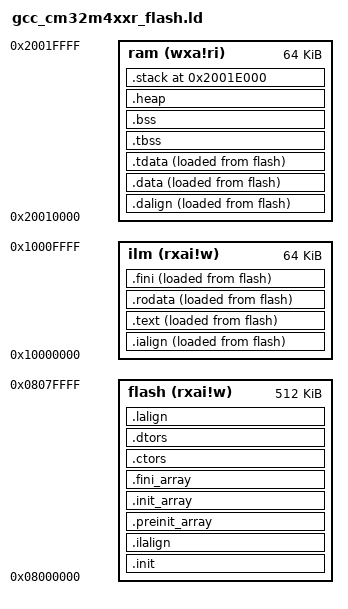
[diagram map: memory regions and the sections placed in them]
/*
 * Copyright (c) 2019 Nuclei Limited. All rights reserved.
 *
 * SPDX-License-Identifier: Apache-2.0
 *
 * Licensed under the Apache License, Version 2.0 (the License); you may
 * not use this file except in compliance with the License.
 * You may obtain a copy of the License at
 *
 * www.apache.org/licenses/LICENSE-2.0
 *
 * Unless required by applicable law or agreed to in writing, software
 * distributed under the License is distributed on an AS IS BASIS, WITHOUT
 * WARRANTIES OR CONDITIONS OF ANY KIND, either express or implied.
 * See the License for the specific language governing permissions and
 * limitations under the License.
 */
/******************************************************************************
 * @file     gcc_cm32m4xxr.ld
 * @brief    GNU Linker Script for Nuclei N/NX based device
 * @version  V1.0.0
 * @date     29. Jun 2020
 ******************************************************************************/

/*********** Use Configuration Wizard in Context Menu *************************/

OUTPUT_ARCH( "riscv" )
/********************* Flash Configuration ************************************
 * <h> Flash Configuration
 * <o0> Flash Base Address <0x0-0xFFFFFFFF:8>
 * <o1> Flash Size (in Bytes) <0x0-0xFFFFFFFF:8>
 * </h>
 */
__FLASH_BASE = 0x08000000;
__FLASH_SIZE = 0x00080000;	/* 512K user flash */

/*--------------------- ILM RAM Configuration ---------------------------
 * <h> ILM RAM Configuration
 * <o0> ILM RAM Base Address    <0x0-0xFFFFFFFF:8>
 * <o1> ILM RAM Size (in Bytes) <0x0-0xFFFFFFFF:8>
 * </h>
 */
__ILM_RAM_BASE = 0x10000000;
__ILM_RAM_SIZE = 0x00010000;	/* When used for code, set its size a proper value.
								   Note that ILM and RAM share 128K space. */

/*--------------------- Embedded RAM Configuration ---------------------------
 * <h> RAM Configuration
 * <o0> RAM Base Address    <0x0-0xFFFFFFFF:8>
 * <o1> RAM Size (in Bytes) <0x0-0xFFFFFFFF:8>
 * </h>
*/
__RAM_BASE = 0x20010000;
__RAM_SIZE = 0x00010000;	/* 128K user ram with one half used for code */

/********************* Stack / Heap Configuration ****************************
 * <h> Stack / Heap Configuration
 * <o0> Stack Size (in Bytes) <0x0-0xFFFFFFFF:8>
 * <o1> Heap Size (in Bytes) <0x0-0xFFFFFFFF:8>
 * </h>
 */
__STACK_SIZE = 0x00002000;	/* 8K stack */

/**************************** end of configuration section ********************/

/* Define base address and length of flash, ilm and ram */
MEMORY
{
  flash(rxai!w) : ORIGIN = __FLASH_BASE, LENGTH = __FLASH_SIZE
  ilm (rxai!w)  : ORIGIN = __ILM_RAM_BASE, LENGTH = __ILM_RAM_SIZE
  ram (wxa!ri)  : ORIGIN = __RAM_BASE, LENGTH = __RAM_SIZE
}
/* Linker script to place sections and symbol values. Should be used together
 * with other linker script that defines memory regions FLASH, ILM and RAM.
 * It references following symbols, which must be defined in code:
 *   _Start : Entry of reset handler
 *
 * It defines following symbols, which code can use without definition:
 *   _ilm_lma
 *   _ilm
 *   __etext
 *   _etext
 *   etext
 *   _eilm
 *   __preinit_array_start
 *   __preinit_array_end
 *   __init_array_start
 *   __init_array_end
 *   __fini_array_start
 *   __fini_array_end
 *   _data_lma
 *   _edata
 *   edata
 *   __data_end__
 *   __bss_start
 *   __fbss
 *   _end
 *   end
 *   __heap_end
 *   __StackLimit
 *   __StackTop
 *   __STACK_SIZE
 */
/* Define entry label of program */
ENTRY(_start)
SECTIONS
{
  __STACK_SIZE = DEFINED(__STACK_SIZE) ? __STACK_SIZE : 2K;
  __HEAP_SIZE = DEFINED(__HEAP_SIZE) ? __HEAP_SIZE : 2K;

  .init           :
  {
    KEEP (*(SORT_NONE(.init)))
  } >flash AT>flash

  .ilalign         :
  {
    . = ALIGN(4);
    /* Create a section label as _ilm_lma which located at local address */
    PROVIDE( _ilm_lma = . );
  } >flash AT>flash

  .ialign         :
  {
    /* Create a section label as _ilm which located at virtual address */
    PROVIDE( _ilm = . );
  } >ilm AT>flash

  /* Code section located at ilm and local address is flash */
  .text           :
  {
    /* vector table locate at ilm */
    *(.vtable)
    *(.text.unlikely .text.unlikely.*)
    *(.text.startup .text.startup.*)
    *(.text .text.*)
    *(.gnu.linkonce.t.*)
  } >ilm AT>flash

  .rodata : ALIGN_WITH_INPUT
  {
    . = ALIGN(4);
    *(.rdata)
    *(.rodata .rodata.*)
    *(.gnu.linkonce.r.*)
  } >ilm AT>flash

  .fini           :
  {
    KEEP (*(SORT_NONE(.fini)))
  } >ilm AT>flash

  . = ALIGN(4);

  PROVIDE (__etext = .);
  PROVIDE (_etext = .);
  PROVIDE (etext = .);
  PROVIDE( _eilm = . );


  .preinit_array  :
  {
    PROVIDE_HIDDEN (__preinit_array_start = .);
    KEEP (*(.preinit_array))
    PROVIDE_HIDDEN (__preinit_array_end = .);
  } >flash AT>flash

  .init_array     :
  {
    PROVIDE_HIDDEN (__init_array_start = .);
    KEEP (*(SORT_BY_INIT_PRIORITY(.init_array.*) SORT_BY_INIT_PRIORITY(.ctors.*)))
    KEEP (*(.init_array EXCLUDE_FILE (*crtbegin.o *crtbegin?.o *crtend.o *crtend?.o ) .ctors))
    PROVIDE_HIDDEN (__init_array_end = .);
  } >flash AT>flash

  .fini_array     :
  {
    PROVIDE_HIDDEN (__fini_array_start = .);
    KEEP (*(SORT_BY_INIT_PRIORITY(.fini_array.*) SORT_BY_INIT_PRIORITY(.dtors.*)))
    KEEP (*(.fini_array EXCLUDE_FILE (*crtbegin.o *crtbegin?.o *crtend.o *crtend?.o ) .dtors))
    PROVIDE_HIDDEN (__fini_array_end = .);
  } >flash AT>flash

  .ctors          :
  {
    /* gcc uses crtbegin.o to find the start of
     * the constructors, so we make sure it is
     * first.  Because this is a wildcard, it
     * doesn't matter if the user does not
     * actually link against crtbegin.o; the
     * linker won't look for a file to match a
     * wildcard.  The wildcard also means that it
     * doesn't matter which directory crtbegin.o
     * is in.
     */
    KEEP (*crtbegin.o(.ctors))
    KEEP (*crtbegin?.o(.ctors))
    /* We don't want to include the .ctor section from
     * the crtend.o file until after the sorted ctors.
     * The .ctor section from the crtend file contains the
     * end of ctors marker and it must be last
     */
    KEEP (*(EXCLUDE_FILE (*crtend.o *crtend?.o ) .ctors))
    KEEP (*(SORT(.ctors.*)))
    KEEP (*(.ctors))
  } >flash AT>flash

  .dtors          :
  {
    KEEP (*crtbegin.o(.dtors))
    KEEP (*crtbegin?.o(.dtors))
    KEEP (*(EXCLUDE_FILE (*crtend.o *crtend?.o ) .dtors))
    KEEP (*(SORT(.dtors.*)))
    KEEP (*(.dtors))
  } >flash AT>flash

  .lalign         :
  {
    . = ALIGN(4);
    PROVIDE( _data_lma = . );
  } >flash AT>flash

  .dalign         :
  {
    . = ALIGN(4);
    PROVIDE( _data = . );
  } >ram AT>flash

  /* Define data section virtual address is ram and local address is flash */
  .data          :
  {
    *(.data .data.*)
    *(.gnu.linkonce.d.*)
    . = ALIGN(8);
    PROVIDE( __global_pointer$ = . + 0x800 );
    *(.sdata .sdata.* .sdata*)
    *(.gnu.linkonce.s.*)
    . = ALIGN(8);
    *(.srodata.cst16)
    *(.srodata.cst8)
    *(.srodata.cst4)
    *(.srodata.cst2)
    *(.srodata .srodata.*)
  } >ram AT>flash

  .tdata           : ALIGN(8)
  {
    PROVIDE( __tls_base = . );
    *(.tdata .tdata.* .gnu.linkonce.td.*)
  } >ram AT>flash

  .tbss (NOLOAD)   : ALIGN(8)
  {
    *(.tbss .tbss.* .gnu.linkonce.tb.*)
    *(.tcommon)
    PROVIDE( __tls_end = . );
  } >ram AT>ram

  . = ALIGN(4);
  PROVIDE( _edata = . );
  PROVIDE( edata = . );

  PROVIDE( _fbss = . );
  PROVIDE( __bss_start = . );
  .bss            : ALIGN(8)
  {
    *(.sbss*)
    *(.gnu.linkonce.sb.*)
    *(.bss .bss.*)
    *(.gnu.linkonce.b.*)
    *(COMMON)
    . = ALIGN(4);
  } >ram AT>ram

  . = ALIGN(8);
  PROVIDE( _end = . );
  PROVIDE( end = . );
  
  /* Nuclei C Runtime Library requirements:
   * 1. heap need to be align at 16 bytes
   * 2. __heap_start and __heap_end symbol need to be defined
   * 3. reserved at least __HEAP_SIZE space for heap
   */
  .heap (NOLOAD) :
  {
    . = ALIGN(16);
    PROVIDE( __heap_start = . );
    . += __HEAP_SIZE;
    . = ALIGN(16);
    PROVIDE( __heap_limit = . );
  } >ram AT>ram
 
  /* Define stack and head location at ram */
  .stack ORIGIN(ram) + LENGTH(ram) - __STACK_SIZE :
  {
    PROVIDE( _heap_end = . );
    PROVIDE( __heap_end = . );
    PROVIDE( __StackLimit = . );
    PROVIDE( __StackBottom = . );
    . += __STACK_SIZE;
    . = ALIGN(16);
    PROVIDE( __StackTop = . );
    PROVIDE( _sp = . );
  } >ram AT>ram
}
